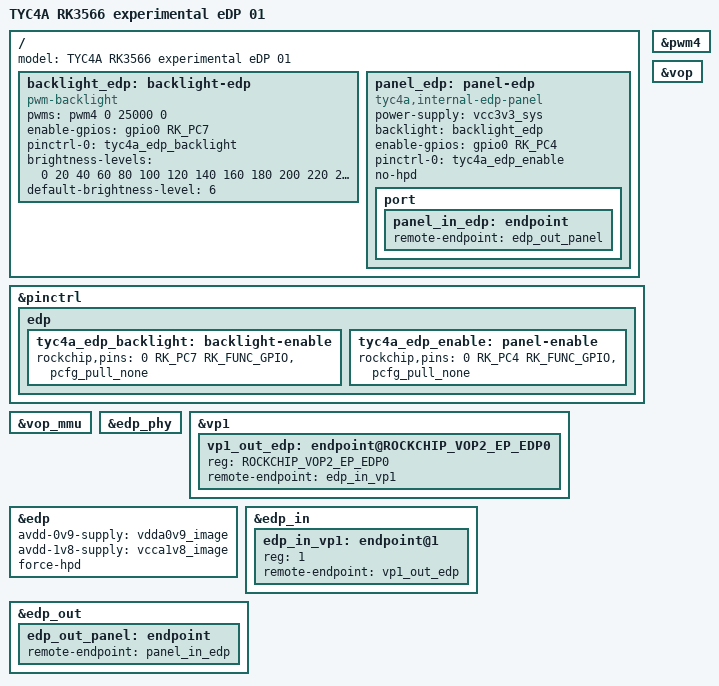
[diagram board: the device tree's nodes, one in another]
// SPDX-License-Identifier: (GPL-2.0+ OR MIT)
// Experimental internal eDP port. Keep the boot-tested diagnostics as fallback.
#include "../diagnostics/rk3566-tyc4a-sd-diagnostics.dts"
#include <dt-bindings/soc/rockchip,vop2.h>

/ {
	model = "TYC4A RK3566 experimental eDP 01";

	backlight_edp: backlight-edp {
		compatible = "pwm-backlight";
		pwms = <&pwm4 0 25000 0>;
		enable-gpios = <&gpio0 RK_PC7 GPIO_ACTIVE_HIGH>;
		pinctrl-names = "default";
		pinctrl-0 = <&tyc4a_edp_backlight>;
		brightness-levels = <0 20 40 60 80 100 120 140 160 180 200 220 240 255>;
		default-brightness-level = <6>;
	};

	panel_edp: panel-edp {
		compatible = "tyc4a,internal-edp-panel";
		power-supply = <&vcc3v3_sys>;
		backlight = <&backlight_edp>;
		enable-gpios = <&gpio0 RK_PC4 GPIO_ACTIVE_HIGH>;
		pinctrl-names = "default";
		pinctrl-0 = <&tyc4a_edp_enable>;
		no-hpd;

		port {
			panel_in_edp: endpoint {
				remote-endpoint = <&edp_out_panel>;
			};
		};
	};
};

&pinctrl {
	edp {
		tyc4a_edp_backlight: backlight-enable {
			rockchip,pins = <0 RK_PC7 RK_FUNC_GPIO &pcfg_pull_none>;
		};
		tyc4a_edp_enable: panel-enable {
			rockchip,pins = <0 RK_PC4 RK_FUNC_GPIO &pcfg_pull_none>;
		};
	};
};

&pwm4 { status = "okay"; };
&vop { status = "okay"; };
&vop_mmu { status = "okay"; };
&edp_phy { status = "okay"; };

&vp1 {
	vp1_out_edp: endpoint@ROCKCHIP_VOP2_EP_EDP0 {
		reg = <ROCKCHIP_VOP2_EP_EDP0>;
		remote-endpoint = <&edp_in_vp1>;
	};
};

&edp {
	avdd-0v9-supply = <&vdda0v9_image>;
	avdd-1v8-supply = <&vcca1v8_image>;
	force-hpd;
	status = "okay";
};

&edp_in {
	#address-cells = <1>;
	#size-cells = <0>;
	edp_in_vp1: endpoint@1 {
		reg = <1>;
		remote-endpoint = <&vp1_out_edp>;
	};
};

&edp_out {
	edp_out_panel: endpoint {
		remote-endpoint = <&panel_in_edp>;
	};
};
